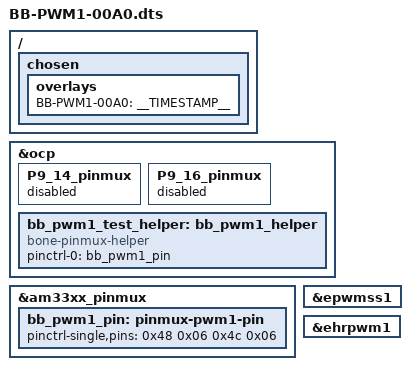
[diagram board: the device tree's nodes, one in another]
/*
 * Copyright (C) 2016 Seeed Studio.
 *
 * This program is free software; you can redistribute it and/or modify
 * it under the terms of the GNU General Public License version 2 as
 * published by the Free Software Foundation.
 */

/dts-v1/;
/plugin/;

#include <dt-bindings/gpio/gpio.h>
#include <dt-bindings/pinctrl/am33xx.h>

/{
	/*
	 * Helper to show loaded overlays under: /proc/device-tree/chosen/overlays/
	 */
	fragment@0 {
		target-path="/";
		__overlay__ {

			chosen {
				overlays {
					BB-PWM1-00A0 = __TIMESTAMP__;
				};
			};
		};
	};

	/*
	 * Free up the pins used by the cape from the pinmux helpers.
	 */
	fragment@1 {
		target = <&ocp>;
		__overlay__ {
			P9_14_pinmux { status = "disabled"; };	/* (U14) gpmc_a2.ehrpwm1A */
			P9_16_pinmux { status = "disabled"; };	/* (T14) gpmc_a3.ehrpwm1B */
		};
	};

	fragment@2 {
		target = <&am33xx_pinmux>;
		__overlay__ {
			bb_pwm1_pin: pinmux-pwm1-pin {
				pinctrl-single,pins = <
					0x48 0x06 /* (U14) gpmc_a2.ehrpwm1A */
					0x4c 0x06 /* (T14) gpmc_a3.ehrpwm1B */
				>;
			};
		};
	};

	fragment@3 {
		target = <&ocp>;
		__overlay__ {
			bb_pwm1_test_helper: bb_pwm1_helper {
				compatible = "bone-pinmux-helper";
				pinctrl-names = "default";
				pinctrl-0 = <&bb_pwm1_pin>;
				status = "okay";
			};
		};
	};

	fragment@4 {
		target = <&epwmss1>;
		__overlay__ {
			status = "okay";
		};
	};

	fragment@5 {
		target = <&ehrpwm1>;
		__overlay__ {
			status = "okay";
		};
	};
};
